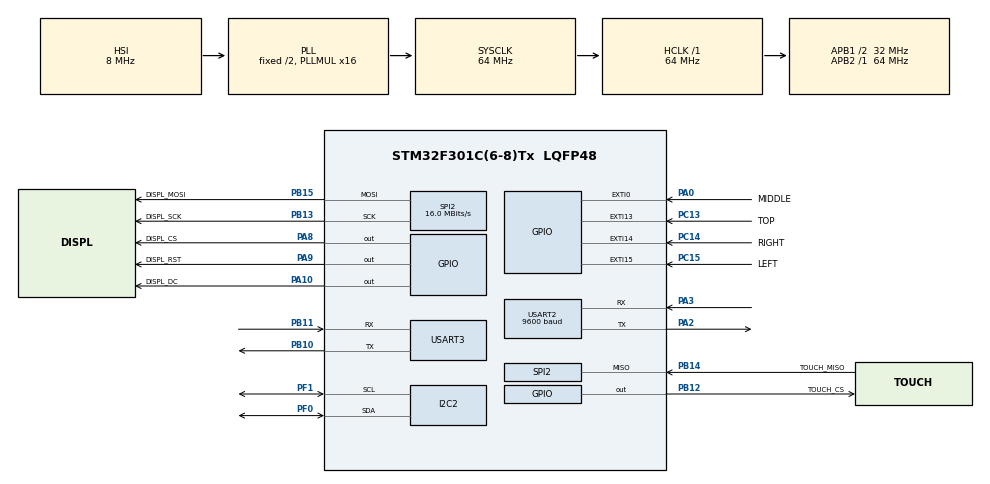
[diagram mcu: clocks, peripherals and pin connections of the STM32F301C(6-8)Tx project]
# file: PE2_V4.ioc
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Dma.Request0=SPI2_TX
Dma.SPI2_TX.0.Direction=DMA_MEMORY_TO_PERIPH
Dma.SPI2_TX.0.Instance=DMA1_Channel5
Dma.SPI2_TX.0.MemDataAlignment=DMA_MDATAALIGN_BYTE
Dma.SPI2_TX.0.MemInc=DMA_MINC_ENABLE
Dma.SPI2_TX.0.Mode=DMA_NORMAL
Dma.SPI2_TX.0.PeriphDataAlignment=DMA_PDATAALIGN_BYTE
Dma.SPI2_TX.0.PeriphInc=DMA_PINC_DISABLE
Dma.SPI2_TX.0.Priority=DMA_PRIORITY_LOW
Mcu.Family=STM32F3
Mcu.Name=STM32F301C(6-8)Tx
Mcu.Package=LQFP48
NVIC.DMA1_Channel5_IRQn=true\:0\:0\:false\:false\:true\:false\:true\:true
NVIC.EXTI0_IRQn=true\:0\:0\:false\:false\:true\:true\:true\:true
NVIC.EXTI15_10_IRQn=true\:0\:0\:false\:false\:true\:true\:true\:true
NVIC.PriorityGroup=NVIC_PRIORITYGROUP_4
NVIC.SPI2_IRQn=true\:0\:0\:false\:false\:true\:true\:true\:true
NVIC.USART2_IRQn=true\:0\:0\:false\:false\:true\:true\:true\:true
PA0.GPIO_Label=MIDDLE
PA0.GPIO_ModeDefaultEXTI=GPIO_MODE_IT_FALLING
PA0.GPIO_PuPd=GPIO_PULLUP
PA0.Signal=GPXTI0
PA10.GPIO_Label=DISPL_DC
PA10.Signal=GPIO_Output
PA13.Mode=Trace_Asynchronous_SW
PA13.Signal=SYS_JTMS-SWDIO
PA14.Mode=Trace_Asynchronous_SW
PA14.Signal=SYS_JTCK-SWCLK
PA2.Mode=Asynchronous
PA2.Signal=USART2_TX
PA3.Mode=Asynchronous
PA3.Signal=USART2_RX
PA8.GPIO_Label=DISPL_CS
PA8.Signal=GPIO_Output
PA9.GPIO_Label=DISPL_RST
PA9.Signal=GPIO_Output
PB10.Mode=Asynchronous
PB10.Signal=USART3_TX
PB11.Mode=Asynchronous
PB11.Signal=USART3_RX
PB12.GPIO_Label=TOUCH_CS
PB12.Signal=GPIO_Output
PB13.GPIO_Label=DISPL_SCK
PB13.Mode=Full_Duplex_Master
PB13.Signal=SPI2_SCK
PB14.GPIO_Label=TOUCH_MISO
PB14.Mode=Full_Duplex_Master
PB14.Signal=SPI2_MISO
PB15.GPIO_Label=DISPL_MOSI
PB15.Mode=Full_Duplex_Master
PB15.Signal=SPI2_MOSI
PB3.Mode=Trace_Asynchronous_SW
PB3.Signal=SYS_JTDO-TRACESWO
PC13.GPIO_Label=TOP
PC13.GPIO_ModeDefaultEXTI=GPIO_MODE_IT_FALLING
PC13.GPIO_PuPd=GPIO_PULLUP
PC13.Signal=GPXTI13
PC14\ -\ OSC32_IN.GPIO_Label=RIGHT
PC14\ -\ OSC32_IN.GPIO_ModeDefaultEXTI=GPIO_MODE_IT_FALLING
PC14\ -\ OSC32_IN.GPIO_PuPd=GPIO_PULLUP
PC14\ -\ OSC32_IN.Signal=GPXTI14
PC15\ -\ OSC32_OUT.GPIO_Label=LEFT
PC15\ -\ OSC32_OUT.GPIO_ModeDefaultEXTI=GPIO_MODE_IT_FALLING
PC15\ -\ OSC32_OUT.GPIO_PuPd=GPIO_PULLUP
PC15\ -\ OSC32_OUT.Signal=GPXTI15
PF0-OSC_IN.GPIO_Pu=GPIO_PULLUP
PF0-OSC_IN.GPIO_Speed=GPIO_SPEED_FREQ_HIGH
PF0-OSC_IN.Mode=I2C
PF0-OSC_IN.Signal=I2C2_SDA
PF1-OSC_OUT.GPIO_Pu=GPIO_PULLUP
PF1-OSC_OUT.GPIO_Speed=GPIO_SPEED_FREQ_HIGH
PF1-OSC_OUT.Mode=I2C
PF1-OSC_OUT.Signal=I2C2_SCL
ProjectManager.HeapSize=0x200
ProjectManager.StackSize=0x400
ProjectManager.TargetToolchain=STM32CubeIDE
RCC.AHBFreq_Value=64000000
RCC.APB1CLKDivider=RCC_HCLK_DIV2
RCC.APB1Freq_Value=32000000
RCC.APB1TimFreq_Value=64000000
RCC.APB2Freq_Value=64000000
RCC.APB2TimFreq_Value=64000000
RCC.CortexFreq_Value=64000000
RCC.HCLKFreq_Value=64000000
RCC.HSE_VALUE=8000000
RCC.HSI_VALUE=8000000
RCC.LSE_VALUE=32768
RCC.PLLMUL=RCC_PLL_MUL16
RCC.SYSCLKFreq_VALUE=64000000
RCC.SYSCLKSourceVirtual=RCC_SYSCLKSOURCE_PLLCLK
SPI2.BaudRatePrescaler=SPI_BAUDRATEPRESCALER_2
SPI2.CalculateBaudRate=16.0 MBits/s
SPI2.DataSize=SPI_DATASIZE_8BIT
SPI2.Direction=SPI_DIRECTION_2LINES
SPI2.Mode=SPI_MODE_MASTER
SPI2.VirtualType=VM_MASTER
USART2.BaudRate=9600
USART2.VirtualMode-Asynchronous=VM_ASYNC
USART3.VirtualMode-Asynchronous=VM_ASYNC
board=custom

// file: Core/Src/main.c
/* USER CODE BEGIN Header */
/**
  ******************************************************************************
  * @file           : main.c
  * @brief          : Main program body
  ******************************************************************************
  * @attention
  *
  * Copyright (c) 2024 STMicroelectronics.
  * All rights reserved.
  *
  * This software is licensed under terms that can be found in the LICENSE file
  * in the root directory of this software component.
  * If no LICENSE file comes with this software, it is provided AS-IS.
  *
  ******************************************************************************
  */
/* USER CODE END Header */
#include "main.h"

/* USER CODE BEGIN Includes */
#include "debug.h"
/* USER CODE END Includes */

I2C_HandleTypeDef hi2c2;

SPI_HandleTypeDef hspi2;
DMA_HandleTypeDef hdma_spi2_tx;

UART_HandleTypeDef huart2;
UART_HandleTypeDef huart3;

void SystemClock_Config(void);
static void MX_GPIO_Init(void);
static void MX_DMA_Init(void);
static void MX_I2C2_Init(void);
static void MX_SPI2_Init(void);
static void MX_USART2_UART_Init(void);
static void MX_USART3_UART_Init(void);

int main(void)
{

  /* MCU Configuration--------------------------------------------------------*/

  /* Reset of all peripherals, Initializes the Flash interface and the Systick. */
  HAL_Init();

  /* Configure the system clock */
  SystemClock_Config();

  /* Initialize all configured peripherals */
  MX_GPIO_Init();
  MX_DMA_Init();
  MX_I2C2_Init();
  MX_SPI2_Init();
  MX_USART2_UART_Init();
  MX_USART3_UART_Init();

  /* Infinite loop */
  /* USER CODE BEGIN WHILE */
  HAL_UART_Transmit(&huart2, "Hello\r\n", sizeof("Hello\r\n"), 300);
  while (1)
  {
      //printf("test\r\n");
      //HAL_UART_Transmit(&huart2, (uint8_t *)"Hello, I am under the water\r\n", sizeof("Hello, I am under the water\r\n"), 300);
      HAL_Delay(5000);
    /* USER CODE END WHILE */

  }
}

void SystemClock_Config(void)
{
  RCC_OscInitTypeDef RCC_OscInitStruct = {0};
  RCC_ClkInitTypeDef RCC_ClkInitStruct = {0};
  RCC_PeriphCLKInitTypeDef PeriphClkInit = {0};

  /** Initializes the RCC Oscillators according to the specified parameters
  * in the RCC_OscInitTypeDef structure.
  */
  RCC_OscInitStruct.OscillatorType = RCC_OSCILLATORTYPE_HSI;
  RCC_OscInitStruct.HSIState = RCC_HSI_ON;
  RCC_OscInitStruct.HSICalibrationValue = RCC_HSICALIBRATION_DEFAULT;
  RCC_OscInitStruct.PLL.PLLState = RCC_PLL_ON;
  RCC_OscInitStruct.PLL.PLLSource = RCC_PLLSOURCE_HSI;
  RCC_OscInitStruct.PLL.PLLMUL = RCC_PLL_MUL16;
  if (HAL_RCC_OscConfig(&RCC_OscInitStruct) != HAL_OK)
  {
    Error_Handler();
  }

  /** Initializes the CPU, AHB and APB buses clocks
  */
  RCC_ClkInitStruct.ClockType = RCC_CLOCKTYPE_HCLK|RCC_CLOCKTYPE_SYSCLK
                              |RCC_CLOCKTYPE_PCLK1|RCC_CLOCKTYPE_PCLK2;
  RCC_ClkInitStruct.SYSCLKSource = RCC_SYSCLKSOURCE_PLLCLK;
  RCC_ClkInitStruct.AHBCLKDivider = RCC_SYSCLK_DIV1;
  RCC_ClkInitStruct.APB1CLKDivider = RCC_HCLK_DIV2;
  RCC_ClkInitStruct.APB2CLKDivider = RCC_HCLK_DIV1;

  if (HAL_RCC_ClockConfig(&RCC_ClkInitStruct, FLASH_LATENCY_2) != HAL_OK)
  {
    Error_Handler();
  }
  PeriphClkInit.PeriphClockSelection = RCC_PERIPHCLK_I2C2;
  PeriphClkInit.I2c2ClockSelection = RCC_I2C2CLKSOURCE_HSI;
  if (HAL_RCCEx_PeriphCLKConfig(&PeriphClkInit) != HAL_OK)
  {
    Error_Handler();
  }
}

static void MX_I2C2_Init(void)
{

  hi2c2.Instance = I2C2;
  hi2c2.Init.Timing = 0x2000090E;
  hi2c2.Init.OwnAddress1 = 0;
  hi2c2.Init.AddressingMode = I2C_ADDRESSINGMODE_7BIT;
  hi2c2.Init.DualAddressMode = I2C_DUALADDRESS_DISABLE;
  hi2c2.Init.OwnAddress2 = 0;
  hi2c2.Init.OwnAddress2Masks = I2C_OA2_NOMASK;
  hi2c2.Init.GeneralCallMode = I2C_GENERALCALL_DISABLE;
  hi2c2.Init.NoStretchMode = I2C_NOSTRETCH_DISABLE;
  if (HAL_I2C_Init(&hi2c2) != HAL_OK)
  {
    Error_Handler();
  }

  /** Configure Analogue filter
  */
  if (HAL_I2CEx_ConfigAnalogFilter(&hi2c2, I2C_ANALOGFILTER_ENABLE) != HAL_OK)
  {
    Error_Handler();
  }

  /** Configure Digital filter
  */
  if (HAL_I2CEx_ConfigDigitalFilter(&hi2c2, 0) != HAL_OK)
  {
    Error_Handler();
  }

}

static void MX_SPI2_Init(void)
{

  /* SPI2 parameter configuration*/
  hspi2.Instance = SPI2;
  hspi2.Init.Mode = SPI_MODE_MASTER;
  hspi2.Init.Direction = SPI_DIRECTION_2LINES;
  hspi2.Init.DataSize = SPI_DATASIZE_8BIT;
  hspi2.Init.CLKPolarity = SPI_POLARITY_LOW;
  hspi2.Init.CLKPhase = SPI_PHASE_1EDGE;
  hspi2.Init.NSS = SPI_NSS_SOFT;
  hspi2.Init.BaudRatePrescaler = SPI_BAUDRATEPRESCALER_2;
  hspi2.Init.FirstBit = SPI_FIRSTBIT_MSB;
  hspi2.Init.TIMode = SPI_TIMODE_DISABLE;
  hspi2.Init.CRCCalculation = SPI_CRCCALCULATION_DISABLE;
  hspi2.Init.CRCPolynomial = 7;
  hspi2.Init.CRCLength = SPI_CRC_LENGTH_DATASIZE;
  hspi2.Init.NSSPMode = SPI_NSS_PULSE_ENABLE;
  if (HAL_SPI_Init(&hspi2) != HAL_OK)
  {
    Error_Handler();
  }

}

static void MX_USART2_UART_Init(void)
{

  huart2.Instance = USART2;
  huart2.Init.BaudRate = 9600;
  huart2.Init.WordLength = UART_WORDLENGTH_8B;
  huart2.Init.StopBits = UART_STOPBITS_1;
  huart2.Init.Parity = UART_PARITY_NONE;
  huart2.Init.Mode = UART_MODE_TX_RX;
  huart2.Init.HwFlowCtl = UART_HWCONTROL_NONE;
  huart2.Init.OverSampling = UART_OVERSAMPLING_16;
  huart2.Init.OneBitSampling = UART_ONE_BIT_SAMPLE_DISABLE;
  huart2.AdvancedInit.AdvFeatureInit = UART_ADVFEATURE_NO_INIT;
  if (HAL_UART_Init(&huart2) != HAL_OK)
  {
    Error_Handler();
  }
  /* USER CODE BEGIN USART2_Init 2 */
  USART2->CR1 |= (USART_CR1_TE | USART_CR1_RXNEIE | USART_CR1_RE | USART_CR1_UE);
  /* USER CODE END USART2_Init 2 */

}

static void MX_USART3_UART_Init(void)
{

  huart3.Instance = USART3;
  huart3.Init.BaudRate = 38400;
  huart3.Init.WordLength = UART_WORDLENGTH_8B;
  huart3.Init.StopBits = UART_STOPBITS_1;
  huart3.Init.Parity = UART_PARITY_NONE;
  huart3.Init.Mode = UART_MODE_TX_RX;
  huart3.Init.HwFlowCtl = UART_HWCONTROL_NONE;
  huart3.Init.OverSampling = UART_OVERSAMPLING_16;
  huart3.Init.OneBitSampling = UART_ONE_BIT_SAMPLE_DISABLE;
  huart3.AdvancedInit.AdvFeatureInit = UART_ADVFEATURE_NO_INIT;
  if (HAL_UART_Init(&huart3) != HAL_OK)
  {
    Error_Handler();
  }

}

static void MX_DMA_Init(void)
{

  /* DMA controller clock enable */
  __HAL_RCC_DMA1_CLK_ENABLE();

  /* DMA interrupt init */
  /* DMA1_Channel5_IRQn interrupt configuration */
  HAL_NVIC_SetPriority(DMA1_Channel5_IRQn, 0, 0);
  HAL_NVIC_EnableIRQ(DMA1_Channel5_IRQn);

}

static void MX_GPIO_Init(void)
{
  GPIO_InitTypeDef GPIO_InitStruct = {0};

  /* GPIO Ports Clock Enable */
  __HAL_RCC_GPIOC_CLK_ENABLE();
  __HAL_RCC_GPIOF_CLK_ENABLE();
  __HAL_RCC_GPIOA_CLK_ENABLE();
  __HAL_RCC_GPIOB_CLK_ENABLE();

  /*Configure GPIO pin Output Level */
  HAL_GPIO_WritePin(TOUCH_CS_GPIO_Port, TOUCH_CS_Pin, GPIO_PIN_RESET);

  /*Configure GPIO pin Output Level */
  HAL_GPIO_WritePin(GPIOA, DISPL_CS_Pin|DISPL_RST_Pin|DISPL_DC_Pin, GPIO_PIN_RESET);

  /*Configure GPIO pins : TOP_Pin RIGHT_Pin LEFT_Pin */
  GPIO_InitStruct.Pin = TOP_Pin|RIGHT_Pin|LEFT_Pin;
  GPIO_InitStruct.Mode = GPIO_MODE_IT_FALLING;
  GPIO_InitStruct.Pull = GPIO_PULLUP;
  HAL_GPIO_Init(GPIOC, &GPIO_InitStruct);

  /*Configure GPIO pin : MIDDLE_Pin */
  GPIO_InitStruct.Pin = MIDDLE_Pin;
  GPIO_InitStruct.Mode = GPIO_MODE_IT_FALLING;
  GPIO_InitStruct.Pull = GPIO_PULLUP;
  HAL_GPIO_Init(MIDDLE_GPIO_Port, &GPIO_InitStruct);

  /*Configure GPIO pin : TOUCH_CS_Pin */
  GPIO_InitStruct.Pin = TOUCH_CS_Pin;
  GPIO_InitStruct.Mode = GPIO_MODE_OUTPUT_PP;
  GPIO_InitStruct.Pull = GPIO_NOPULL;
  GPIO_InitStruct.Speed = GPIO_SPEED_FREQ_LOW;
  HAL_GPIO_Init(TOUCH_CS_GPIO_Port, &GPIO_InitStruct);

  /*Configure GPIO pins : DISPL_CS_Pin DISPL_RST_Pin DISPL_DC_Pin */
  GPIO_InitStruct.Pin = DISPL_CS_Pin|DISPL_RST_Pin|DISPL_DC_Pin;
  GPIO_InitStruct.Mode = GPIO_MODE_OUTPUT_PP;
  GPIO_InitStruct.Pull = GPIO_NOPULL;
  GPIO_InitStruct.Speed = GPIO_SPEED_FREQ_LOW;
  HAL_GPIO_Init(GPIOA, &GPIO_InitStruct);

  /* EXTI interrupt init*/
  HAL_NVIC_SetPriority(EXTI0_IRQn, 0, 0);
  HAL_NVIC_EnableIRQ(EXTI0_IRQn);

  HAL_NVIC_SetPriority(EXTI15_10_IRQn, 0, 0);
  HAL_NVIC_EnableIRQ(EXTI15_10_IRQn);

}

void Error_Handler(void)
{
  __disable_irq();
  while (1)
  {
  }
}
